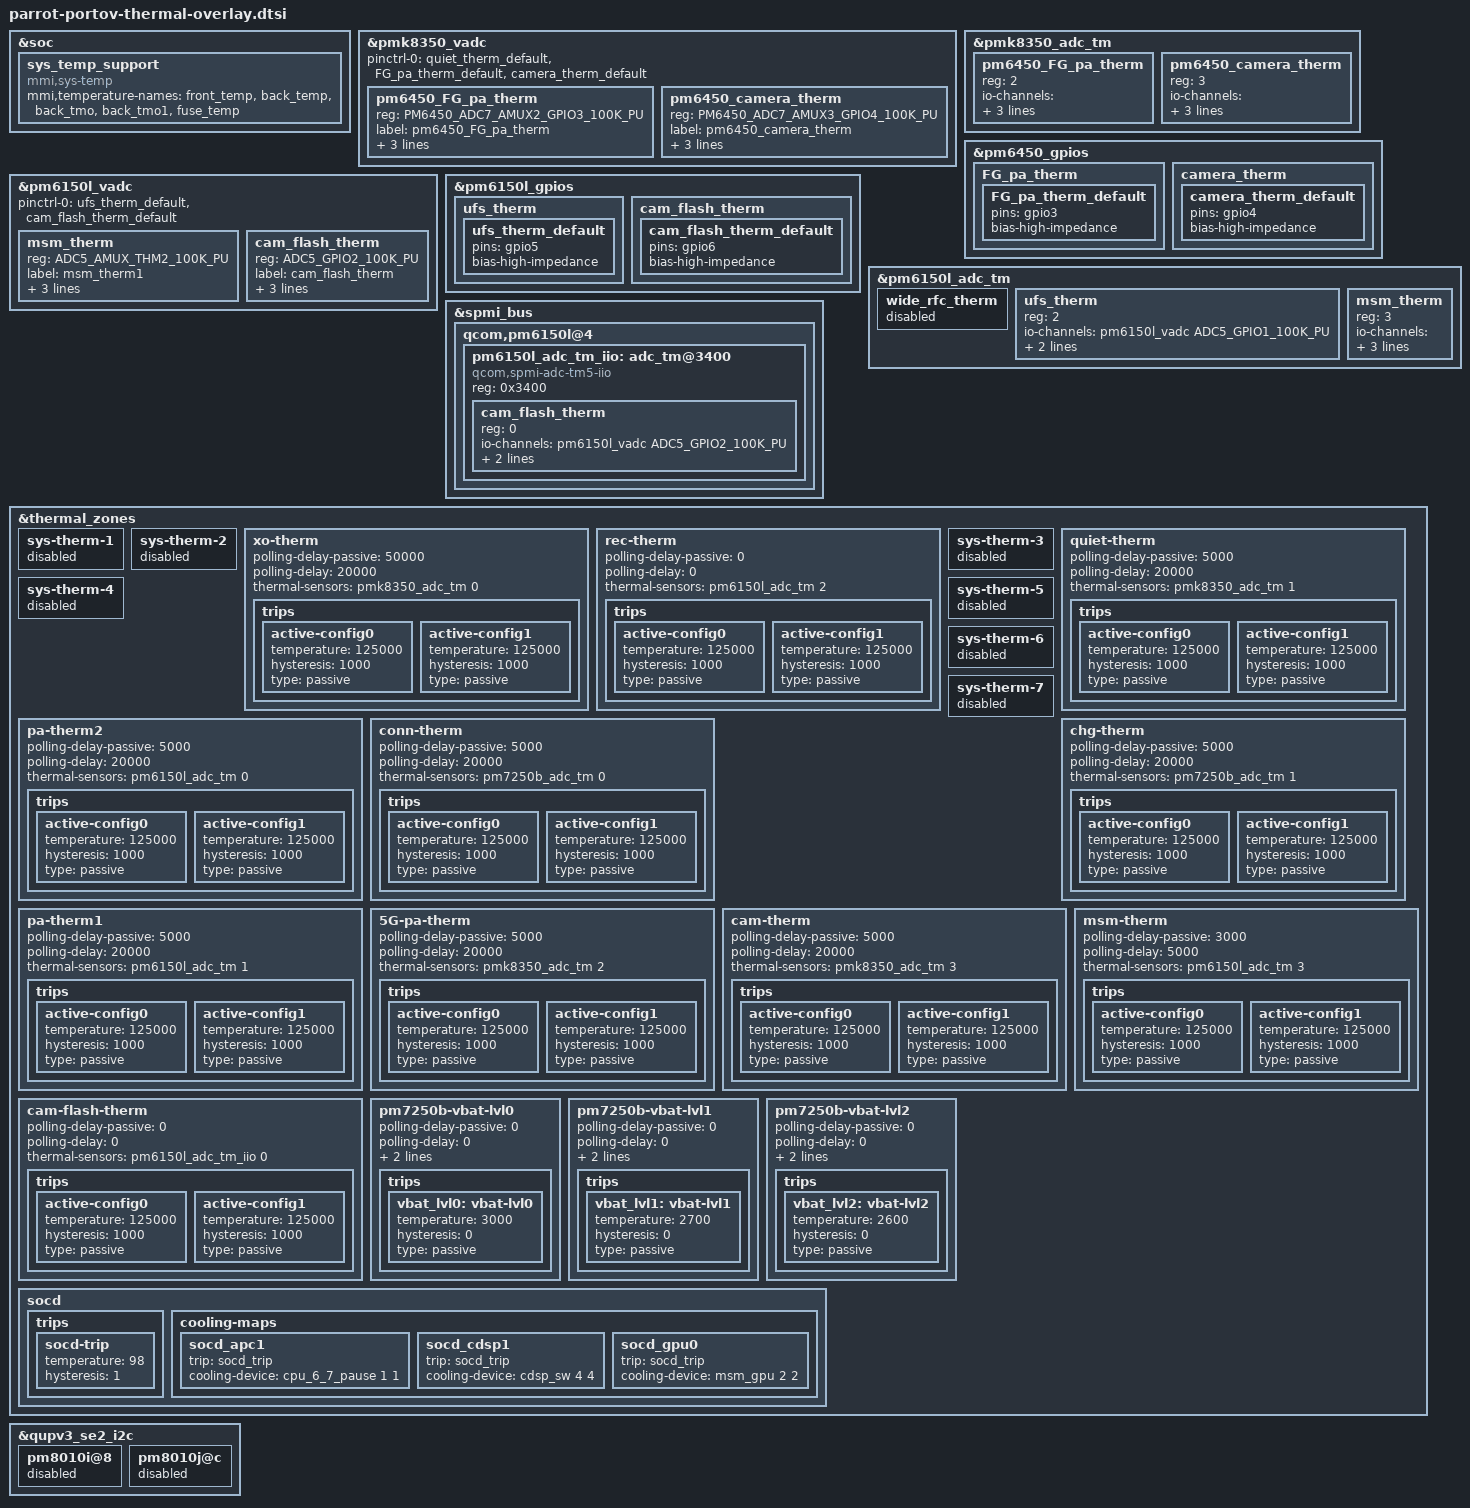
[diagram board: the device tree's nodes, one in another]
&soc {
	sys_temp_support {
		compatible = "mmi,sys-temp";
		mmi,temperature-names = "front_temp",
			"back_temp",
			"back_tmo",
			"back_tmo1",
			"fuse_temp";
		status = "ok";
	};
};

&pmk8350_vadc {
	pinctrl-names = "default";
	pinctrl-0 = <&quiet_therm_default &FG_pa_therm_default &camera_therm_default>;

	pm6450_FG_pa_therm {
		reg = <PM6450_ADC7_AMUX2_GPIO3_100K_PU>;
		label = "pm6450_FG_pa_therm";
		qcom,ratiometric;
		qcom,hw-settle-time = <200>;
		qcom,pre-scaling = <1 1>;
	};

	pm6450_camera_therm {
		reg = <PM6450_ADC7_AMUX3_GPIO4_100K_PU>;
		label = "pm6450_camera_therm";
		qcom,ratiometric;
		qcom,hw-settle-time = <200>;
		qcom,pre-scaling = <1 1>;
	};
};

&pmk8350_adc_tm {
	pm6450_FG_pa_therm {
		reg = <2>;
		io-channels = <&pmk8350_vadc PM6450_ADC7_AMUX2_GPIO3_100K_PU>;
		qcom,ratiometric;
		qcom,hw-settle-time = <200>;
	};

	pm6450_camera_therm {
		reg = <3>;
		io-channels = <&pmk8350_vadc PM6450_ADC7_AMUX3_GPIO4_100K_PU>;
		qcom,ratiometric;
		qcom,hw-settle-time = <200>;
	};
};

&pm6450_gpios {
	FG_pa_therm {
		FG_pa_therm_default: FG_pa_therm_default {
			pins = "gpio3";
			bias-high-impedance;
		};
	};

	camera_therm {
		camera_therm_default: camera_therm_default {
			pins = "gpio4";
			bias-high-impedance;
		};
	};
};

&pm6150l_vadc {
	pinctrl-names = "default";
	pinctrl-0 = <&ufs_therm_default &cam_flash_therm_default>;

	msm_therm {
		reg = <ADC5_AMUX_THM2_100K_PU>;
		label = "msm_therm1";
		qcom,ratiometric;
		qcom,hw-settle-time = <200>;
		qcom,pre-scaling = <1 1>;
	};

	cam_flash_therm {
		reg = <ADC5_GPIO2_100K_PU>;
		label = "cam_flash_therm";
		qcom,ratiometric;
		qcom,hw-settle-time = <200>;
		qcom,pre-scaling = <1 1>;
	};
};

&pm6150l_gpios {
	ufs_therm {
		ufs_therm_default: ufs_therm_default {
			pins = "gpio5";
			bias-high-impedance;
		};
	};

	cam_flash_therm {
		cam_flash_therm_default: cam_flash_therm_default {
			pins = "gpio6";
			bias-high-impedance;
		};
	};
};

&pm6150l_adc_tm {
	wide_rfc_therm {
		status = "disabled";
	};

	ufs_therm {
		reg = <2>;
		io-channels = <&pm6150l_vadc ADC5_GPIO1_100K_PU>;
		qcom,ratiometric;
		qcom,hw-settle-time-us = <200>;
	};

	msm_therm {
		reg = <3>;
		io-channels = <&pm6150l_vadc ADC5_AMUX_THM2_100K_PU>;
		qcom,ratiometric;
		qcom,hw-settle-time-us = <200>;
	};
};

&spmi_bus {
	qcom,pm6150l@4 {
		pm6150l_adc_tm_iio: adc_tm@3400 {
			compatible = "qcom,spmi-adc-tm5-iio";
			reg = <0x3400>;
			#thermal-sensor-cells = <1>;
			#address-cells = <1>;
			#size-cells = <0>;

			cam_flash_therm {
				reg = <0>;
				io-channels = <&pm6150l_vadc ADC5_GPIO2_100K_PU>;
				qcom,ratiometric;
				qcom,hw-settle-time-us = <200>;
			};
		};
	};
};

&thermal_zones {
	sys-therm-1 {
		status = "disabled";
	};

	sys-therm-2 {
		status = "disabled";
	};

	xo-therm {
		polling-delay-passive = <50000>;
		polling-delay = <20000>;
		thermal-sensors = <&pmk8350_adc_tm 0>;
		trips {
			active-config0 {
				temperature = <125000>;
				hysteresis = <1000>;
				type = "passive";
			};

			active-config1 {
				temperature = <125000>;
				hysteresis = <1000>;
				type = "passive";
			};
		};
	};

	rec-therm {
		polling-delay-passive = <0>;
		polling-delay = <0>;
		thermal-sensors = <&pm6150l_adc_tm 2>;
		trips {
			active-config0 {
				temperature = <125000>;
				hysteresis = <1000>;
				type = "passive";
			};

			active-config1 {
				temperature = <125000>;
				hysteresis = <1000>;
				type = "passive";
			};
		};
	};

	sys-therm-3 {
		status = "disabled";
	};

	quiet-therm {
		polling-delay-passive = <5000>;
		polling-delay = <20000>;
		thermal-sensors = <&pmk8350_adc_tm 1 >; //PM6450_ADC7_AMUX1_GPIO2_100K_PU
		trips {
			active-config0 {
				temperature = <125000>;
				hysteresis = <1000>;
				type = "passive";
			};

			active-config1 {
				temperature = <125000>;
				hysteresis = <1000>;
				type = "passive";
			};
		};
	};

	sys-therm-4 {
		status = "disabled";
	};

	pa-therm2 {
		polling-delay-passive = <5000>;
		polling-delay = <20000>;
		thermal-sensors = <&pm6150l_adc_tm 0>; //ADC5_AMUX_THM1_100K_PU
		trips {
			active-config0 {
				temperature = <125000>;
				hysteresis = <1000>;
				type = "passive";
			};

			active-config1 {
				temperature = <125000>;
				hysteresis = <1000>;
				type = "passive";
			};
		};
	};

	sys-therm-5 {
		status = "disabled";
	};

	sys-therm-6 {
		status = "disabled";
	};

	sys-therm-7 {
		status = "disabled";
	};

	conn-therm {
		polling-delay-passive = <5000>;
		polling-delay = <20000>;
		thermal-sensors =  <&pm7250b_adc_tm 0>;
		trips {
			active-config0 {
				temperature = <125000>;
				hysteresis = <1000>;
				type = "passive";
			};

			active-config1 {
				temperature = <125000>;
				hysteresis = <1000>;
				type = "passive";
			};
		};
	};

	chg-therm {
		polling-delay-passive = <5000>;
		polling-delay = <20000>;
		thermal-sensors =  <&pm7250b_adc_tm 1>;
		trips {
			active-config0 {
				temperature = <125000>;
				hysteresis = <1000>;
				type = "passive";
			};

			active-config1 {
				temperature = <125000>;
				hysteresis = <1000>;
				type = "passive";
			};
		};
	};

	pa-therm1 {
		polling-delay-passive = <5000>;
		polling-delay = <20000>;
		thermal-sensors = <&pm6150l_adc_tm 1>; //ADC5_AMUX_THM3_100K_PU
		trips {
			active-config0 {
				temperature = <125000>;
				hysteresis = <1000>;
				type = "passive";
			};

			active-config1 {
				temperature = <125000>;
				hysteresis = <1000>;
				type = "passive";
			};
		};
	};

	5G-pa-therm {
		polling-delay-passive = <5000>;
		polling-delay = <20000>;
		thermal-sensors = <&pmk8350_adc_tm 2>;
		trips {
			active-config0 {
				temperature = <125000>;
				hysteresis = <1000>;
				type = "passive";
			};

			active-config1 {
				temperature = <125000>;
				hysteresis = <1000>;
				type = "passive";
			};
		};
	};

	cam-therm {
		polling-delay-passive = <5000>;
		polling-delay = <20000>;
		thermal-sensors = <&pmk8350_adc_tm 3>;
		trips {
			active-config0 {
				temperature = <125000>;
				hysteresis = <1000>;
				type = "passive";
			};

			active-config1 {
				temperature = <125000>;
				hysteresis = <1000>;
				type = "passive";
			};
		};
	};

	msm-therm {
		polling-delay-passive = <3000>;
		polling-delay = <5000>;
		thermal-sensors = <&pm6150l_adc_tm 3>;
		trips {
			active-config0 {
				temperature = <125000>;
				hysteresis = <1000>;
				type = "passive";
			};

			active-config1 {
				temperature = <125000>;
				hysteresis = <1000>;
				type = "passive";
			};
		};
	};

	cam-flash-therm {
		polling-delay-passive = <0>;
		polling-delay = <0>;
		thermal-sensors = <&pm6150l_adc_tm_iio 0>;
		trips {
			active-config0 {
				temperature = <125000>;
				hysteresis = <1000>;
				type = "passive";
			};

			active-config1 {
				temperature = <125000>;
				hysteresis = <1000>;
				type = "passive";
			};
		};
	};

	pm7250b-vbat-lvl0 {
		polling-delay-passive = <0>;
		polling-delay = <0>;
		thermal-governor = "step_wise";
		thermal-sensors = <&pm7250b_bcl 2>;

		trips {
			vbat_lvl0:vbat-lvl0 {
				temperature = <3000>;
				hysteresis = <0>;
				type = "passive";
			};
		};
	};

	pm7250b-vbat-lvl1 {
		polling-delay-passive = <0>;
		polling-delay = <0>;
		thermal-governor = "step_wise";
		thermal-sensors = <&pm7250b_bcl 3>;

		trips {
			vbat_lvl1:vbat-lvl1 {
				temperature = <2700>;
				hysteresis = <0>;
				type = "passive";
			};
		};
	};

	pm7250b-vbat-lvl2 {
		polling-delay-passive = <0>;
		polling-delay = <0>;
		thermal-governor = "step_wise";
		thermal-sensors = <&pm7250b_bcl 4>;

		trips {
			vbat_lvl2:vbat-lvl2 {
				temperature = <2600>;
				hysteresis = <0>;
				type = "passive";
			};
		};
	};

	socd {
		trips {
			socd-trip {
				temperature = <98>;
				hysteresis = <1>;
			};
		};

		cooling-maps {
			socd_apc1 {
				trip = <&socd_trip>;
				cooling-device = <&cpu_6_7_pause 1 1>;
			};

			socd_cdsp1 {
				trip = <&socd_trip>;
				cooling-device = <&cdsp_sw 4 4>;
			};

			socd_gpu0 {
				trip = <&socd_trip>;
				cooling-device = <&msm_gpu 2 2>;
			};
		};
	};
};

&qupv3_se2_i2c {
	pm8010i@8 {
		status = "disabled";
	};
	pm8010j@c {
		status = "disabled";
	};
};
